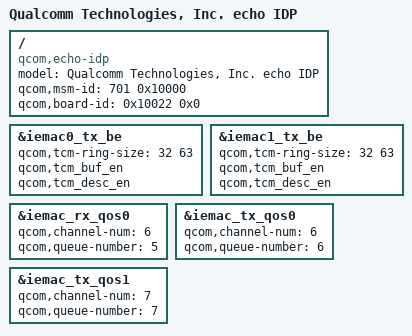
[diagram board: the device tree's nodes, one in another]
// SPDX-License-Identifier: BSD-3-Clause
/*
 * Copyright (c) Qualcomm Technologies, Inc. and/or its subsidiaries.
 */

/dts-v1/;
/plugin/;

#include "echo-eth.dtsi"

/ {
	model = "Qualcomm Technologies, Inc. echo IDP";
	compatible = "qcom,echo-idp",
		"qcom,echo", "qcom,idp";
	qcom,msm-id = <701 0x10000>;
	qcom,board-id = <0x10022 0x0>;

};

&iemac0_tx_be {
	qcom,tcm-ring-size = <32 63>;
	qcom,tcm_buf_en;
	qcom,tcm_desc_en;
};

&iemac1_tx_be {
	qcom,tcm-ring-size = <32 63>;
	qcom,tcm_buf_en;
	qcom,tcm_desc_en;
};

&iemac_rx_qos0 {
	qcom,channel-num = <6>;
	qcom,queue-number = <5>;

};

&iemac_tx_qos0 {
	qcom,channel-num = <6>;
	qcom,queue-number = <6>;
};

&iemac_tx_qos1 {
	qcom,channel-num = <7>;
	qcom,queue-number = <7>;
};
